VERSION ""

NS_ :

BS_:

BU_: PC CHASSIS

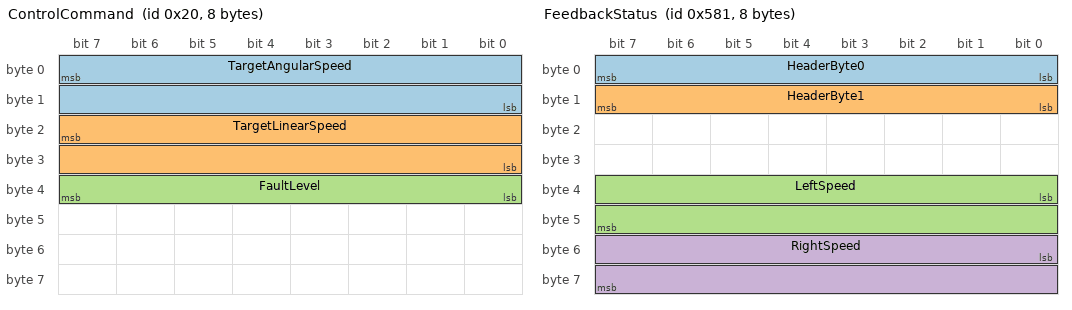
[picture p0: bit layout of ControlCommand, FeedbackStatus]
BO_ 32 ControlCommand: 8 PC
 SG_ TargetAngularSpeed : 7|16@0- (0.01,0) [-327.68|327.67] "rad/s" Vector__XXX
 SG_ TargetLinearSpeed : 23|16@0- (0.001,0) [-32.768|32.767] "m/s" Vector__XXX
 SG_ FaultLevel : 39|8@0+ (1,0) [0|255] "" Vector__XXX

BO_ 1409 FeedbackStatus: 8 CHASSIS
 SG_ HeaderByte0 : 7|8@0+ (1,0) [0|255] "hex" Vector__XXX
 SG_ HeaderByte1 : 15|8@0+ (1,0) [0|255] "hex" Vector__XXX
 SG_ LeftSpeed : 32|16@1- (0.1,0) [-3276.8|3276.7] "rpm" Vector__XXX
 SG_ RightSpeed : 48|16@1- (0.1,0) [-3276.8|3276.7] "rpm" Vector__XXX

CM_ SG_ 32 TargetAngularSpeed "Angular speed command, Big Endian (Motorola)";
CM_ SG_ 32 TargetLinearSpeed "Linear speed command, Big Endian (Motorola)";
CM_ SG_ 1409 LeftSpeed "Left wheel speed feedback, Little Endian (Intel)";
CM_ SG_ 1409 RightSpeed "Right wheel speed feedback, Little Endian (Intel)";
